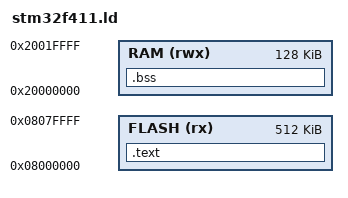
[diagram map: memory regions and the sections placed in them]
/* Minimal linker script: code in flash, data/bss zero-init skipped
   (firmware uses only zero-initialized statics and stack). */
MEMORY
{
  FLASH (rx) : ORIGIN = 0x08000000, LENGTH = 512K
  RAM (rwx)  : ORIGIN = 0x20000000, LENGTH = 128K
}
SECTIONS
{
  .text : { KEEP(*(.vectors)) *(.text*) *(.rodata*) } > FLASH
  .bss (NOLOAD) : { *(.bss*) *(COMMON) } > RAM
}
